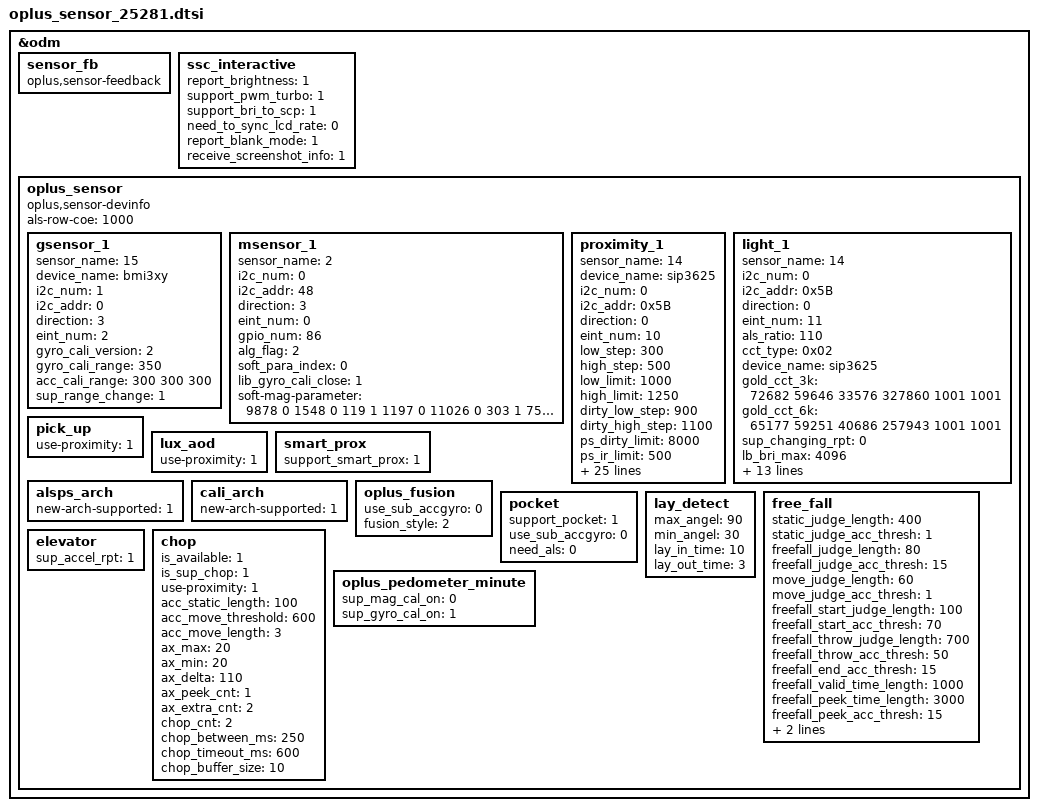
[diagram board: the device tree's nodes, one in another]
&odm {
	sensor_fb: sensor_fb {
		compatible = "oplus,sensor-feedback";
	};
	ssc_interactive: ssc_interactive {
		report_brightness = <1>;
		support_pwm_turbo = <1>;
		support_bri_to_scp = <1>;
		need_to_sync_lcd_rate = <0>;
		report_blank_mode = <1>;
		receive_screenshot_info = <1>;
	};
	oplus_sensor:oplus_sensor {
		compatible = "oplus,sensor-devinfo";
		als-row-coe = <1000>;
		/* sensor start */
       	/*
		enum {
			LIS3DH,
			LSM6DS3,
			BMI160,
			LIS2HH12,
			LSM6DSM,
			BMI2XY,
			LSM6DSO,
			ICM4X6XX,
			ICM4263X,
			SC7A20,
			MC34X9,
			STK8327,
		};
		*/
		gsensor_1: gsensor_1 {
			status = "okay";
			sensor_name = <15>;//BMI3XY
			device_name = "bmi3xy";
			i2c_num = <1>;
			i2c_addr = <0>;
			direction = <3>;
			eint_num = <2>;
			gyro_cali_version= <2>;
			gyro_cali_range =<350>;
			acc_cali_range= <300 300 300>;
			sup_range_change = <1>;
		};
		/*
		enum {
			AKM09911,
			MMC3530,
			MMC5603,
			MXG4300,
		};
		*/
		msensor_1: msensor_1 {
			status = "okay";
			sensor_name = <2>;//MMC5603
			i2c_num = <0>;
			i2c_addr = <48>;
			direction = <3>;
			eint_num = <0>;
			gpio_num = <86>;
			alg_flag = <2>;
			soft_para_index = <0>;
			lib_gyro_cali_close = <1>;
			soft-mag-parameter = <9878 0 1548 0 119 1 1197 0 11026 0 303 1 757 0 475 1 10642 0>;
		};
		/*
		enum {
			TMD2725,
			APSD9922,
			STK3335,
			STK3331,
			STK2232,
			TCS3701,
			STK32600,
			STK33502,
			MN78911,
			SIP3625,
		};
		*/
		proximity_1: proximity_1 {
			status = "okay";
			sensor_name = <14>; //SIP3625
			device_name = "sip3625";
			i2c_num = <0>;
			i2c_addr = <0x5B>;
			direction = <0>;
			eint_num = <10>;
			low_step = <300>;
			high_step = <500>;
			low_limit = <1000>;
			high_limit = <1250>;
			dirty_low_step = <900>;
			dirty_high_step = <1100>;
			ps_dirty_limit = <8000>;
			ps_ir_limit = <500>;
			ps_adjust_min = <350>;
			ps_adjust_max = <1250>;
			sampling_count = <5>;
			step_max = <400>;
			step_min = <100>;
			step_div = <2000>;
			anti_shake_delta = <120>;
			dynamic_cali_max = <2500>;
			raw2offset_radio = <5000>;
			offset_max = <15000>;
			offset_range_min = <0>;
			offset_range_max = <65534>;
			force_cali_limit = <0>;
			cali_jitter_limit = <70>;
			cal_offset_margin = <3000>;
			60hz_psd_us = <13500>;
			90hz_psd_us = <7944>;
			120hz_psd_us = <5166>;
			ps_check_num = <3>;
			ps_mid_filter = <0>;
			need_to_sync_lcd_rate = <0>;
			dmc_flt_thr = <100>;
			multi_oft_level = <3>;
			multi_oft_coef = <130 26 1>;
			ps_power_config = <7>; // BOE
		};
		light_1: light_1 {
			status = "okay";
			sensor_name = <14>; //SIP3625
			i2c_num = <0>;
			i2c_addr = <0x5B>;
			direction = <0>;
			eint_num = <11>;
			als_ratio = <110>;
			cct_type = <0x02>; //0x01 CCT_NORMAL 0x02 CCT_WISE
			device_name = "sip3625";
			gold_cct_3k = <72682 59646 33576 327860 1001 1001>;
			gold_cct_6k = <65177 59251 40686 257943 1001 1001>;
			sup_changing_rpt = <0>;
			lb_bri_max = <4096>;
			ir_ratio = <35>; // *100
			lux_thod = <2000>;//add for high light mode
			idac_thod = <20>;//add for high light mode
			als_coef_ratio = <75>; // *100
			als_delay = <390>;
			available_sensor = <14>;
			gold_cct_factor = <941 946 924 966 1001 1001>;
			high_pwm_cct = <1>;
			als_timer_ms = <100>;
			als_buffer_length = <2>;
			need_gain_cali = <1>;
			atime = <25000>;
			decision_table_index = <3>;
		};
		pick_up: pick_up {
			status = "okay";
			use-proximity = <1>;
		};
		lux_aod: lux_aod {
			status = "okay";
			use-proximity = <1>;
		};
		smart_prox: smart_prox {
			status = "okay";
			support_smart_prox = <1>;
		};
		alsps_arch: alsps_arch {
			status = "okay";
			new-arch-supported = <1>;
		};
		cali_arch: cali_arch {
			status = "okay";
			new-arch-supported = <1>;
		};
		oplus_fusion: oplus_fusion {
			status = "okay";
			use_sub_accgyro = <0>;
			fusion_style = <2>; // 0:vendor fusion; 1:oppo fusion; 2:mix fusion
		};
		pocket: pocket {
			status = "okay";
			support_pocket = <1>;
			use_sub_accgyro = <0>;
			need_als = <0>;
		};
		lay_detect: lay_detect {
			status = "okay";
			max_angel = <90>;
			min_angel = <30>;
			lay_in_time = <10>;
			lay_out_time = <3>;
		};
		free_fall: free_fall {
			status = "okay";
			static_judge_length = <400>;
			static_judge_acc_thresh = <1>;
			freefall_judge_length = <80>;
			freefall_judge_acc_thresh = <15>;
			move_judge_length = <60>;
			move_judge_acc_thresh = <1>;
			freefall_start_judge_length  = <100>;
			freefall_start_acc_thresh = <70>;
			freefall_throw_judge_length = <700>;
			freefall_throw_acc_thresh = <50>;
			freefall_end_acc_thresh = <15>;
			freefall_valid_time_length = <1000>;
			freefall_peek_time_length = <3000>;
			freefall_peek_acc_thresh = <15>;
			freefall_material_thresh = <900>;
			valid_peek_interval_thresh = <10000>;
		};
		elevator: elevator {
			status = "okay";
			sup_accel_rpt = <1>;
		};
		chop: chop {
			status = "okay";
			is_available = <1>;
			is_sup_chop = <1>;
			use-proximity = <1>;
			acc_static_length = <100>;
			acc_move_threshold = <600>;
			acc_move_length = <3>;
			ax_max = <20>;
			ax_min = <20>;
			ax_delta = <110>;
			ax_peek_cnt = <1>;
			ax_extra_cnt = <2>;
			chop_cnt = <2>;
			chop_between_ms = <250>;
			chop_timeout_ms = <600>;
			chop_buffer_size = <10>;
		};
		oplus_pedometer_minute: oplus_pedometer_minute{
			status = "okay";
			sup_mag_cal_on = <0>;
			sup_gyro_cal_on = <1>;
		};
	};
/* sensor end */
};
